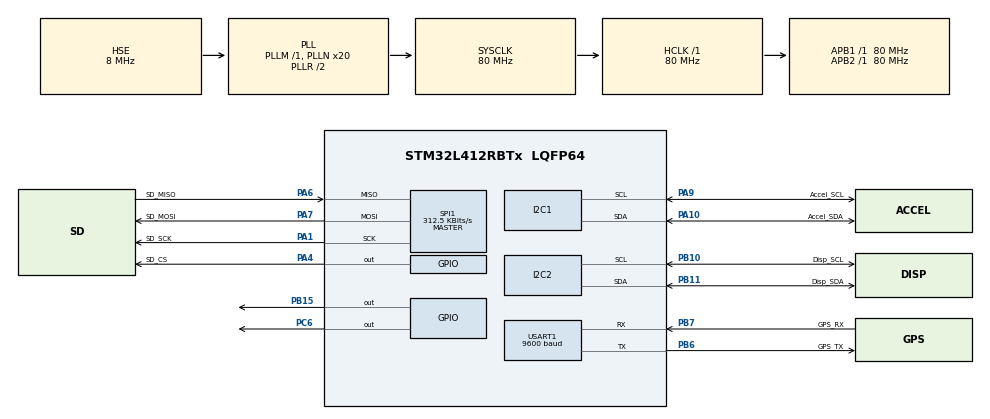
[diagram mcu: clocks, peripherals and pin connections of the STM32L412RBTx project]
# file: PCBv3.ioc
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I2C1.Timing=0x10909CEC
I2C2.Timing=0x10909CEC
Mcu.Family=STM32L4
Mcu.Name=STM32L412RBTx
Mcu.Package=LQFP64
NVIC.PriorityGroup=NVIC_PRIORITYGROUP_4
NVIC.USART1_IRQn=true\:0\:0\:false\:false\:true\:true\:true\:true
PA1.GPIO_Label=SD_SCK
PA1.Mode=Full_Duplex_Master
PA1.Signal=SPI1_SCK
PA10.GPIO_Label=Accel_SDA
PA10.Mode=I2C
PA10.Signal=I2C1_SDA
PA4.GPIO_Label=SD_CS
PA4.Signal=GPIO_Output
PA6.GPIO_Label=SD_MISO
PA6.Mode=Full_Duplex_Master
PA6.Signal=SPI1_MISO
PA7.GPIO_Label=SD_MOSI
PA7.Mode=Full_Duplex_Master
PA7.Signal=SPI1_MOSI
PA9.GPIO_Label=Accel_SCL
PA9.Mode=I2C
PA9.Signal=I2C1_SCL
PB10.GPIO_Label=Disp_SCL
PB10.Mode=I2C
PB10.Signal=I2C2_SCL
PB11.GPIO_Label=Disp_SDA
PB11.Mode=I2C
PB11.Signal=I2C2_SDA
PB15.Signal=GPIO_Output
PB6.GPIO_Label=GPS_TX
PB6.Mode=Asynchronous
PB6.Signal=USART1_TX
PB7.GPIO_Label=GPS_RX
PB7.Mode=Asynchronous
PB7.Signal=USART1_RX
PC6.Signal=GPIO_Output
PH0-OSC_IN\ (PH0).Mode=HSE-External-Oscillator
PH0-OSC_IN\ (PH0).Signal=RCC_OSC_IN
PH1-OSC_OUT\ (PH1).Mode=HSE-External-Oscillator
PH1-OSC_OUT\ (PH1).Signal=RCC_OSC_OUT
ProjectManager.HeapSize=0x2000
ProjectManager.StackSize=0x4000
ProjectManager.TargetToolchain=STM32CubeIDE
RCC.ADCFreq_Value=80000000
RCC.AHBFreq_Value=80000000
RCC.APB1Freq_Value=80000000
RCC.APB1TimFreq_Value=80000000
RCC.APB2Freq_Value=80000000
RCC.APB2TimFreq_Value=80000000
RCC.CortexFreq_Value=80000000
RCC.HCLKFreq_Value=80000000
RCC.HSE_VALUE=8000000
RCC.HSI48_VALUE=48000000
RCC.HSI_VALUE=16000000
RCC.LSE_VALUE=32768
RCC.MSI_VALUE=4000000
RCC.PLLN=20
RCC.PLLSourceVirtual=RCC_PLLSOURCE_HSE
RCC.SYSCLKFreq_VALUE=80000000
RCC.SYSCLKSource=RCC_SYSCLKSOURCE_PLLCLK
RCC.USBFreq_Value=4000000
RCC.VCOOutputFreq_Value=160000000
SPI1.BaudRatePrescaler=SPI_BAUDRATEPRESCALER_256
SPI1.CalculateBaudRate=312.5 KBits/s
SPI1.DataSize=SPI_DATASIZE_8BIT
SPI1.Direction=SPI_DIRECTION_2LINES
SPI1.Mode=SPI_MODE_MASTER
SPI1.VirtualType=VM_MASTER
USART1.BaudRate=9600
USART1.OverrunDisableParam=ADVFEATURE_OVERRUN_DISABLE
USART1.SwapParam=ADVFEATURE_SWAP_DISABLE
USART1.VirtualMode-Asynchronous=VM_ASYNC
VP_FATFS_VS_Generic.Mode=User_defined
board=custom

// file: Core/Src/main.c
/* USER CODE BEGIN Header */
/**
  ******************************************************************************
  * @file           : main.c
  * @brief          : Main program body
  ******************************************************************************
  * @attention
  *
  * Copyright (c) 2023 STMicroelectronics.
  * All rights reserved.
  *
  * This software is licensed under terms that can be found in the LICENSE file
  * in the root directory of this software component.
  * If no LICENSE file comes with this software, it is provided AS-IS.
  *
  ******************************************************************************
  */
/* USER CODE END Header */
#include "main.h"
#include "fatfs.h"

/* USER CODE BEGIN Includes */
#include <string.h>
#include <stdio.h>
#include <stdlib.h>
#include "stm32l4xx.h"
#include "GPS.h"
#include "I2C.h"
#include "ssd1306.h"
#include "lis3dh.h"
#include <stdarg.h>

/* USER CODE END Includes */

I2C_HandleTypeDef hi2c1;
I2C_HandleTypeDef hi2c2;
SPI_HandleTypeDef hspi1;
UART_HandleTypeDef huart1;

HAL_StatusTypeDef status;

void SystemClock_Config(void);
static void MX_GPIO_Init(void);
static void MX_I2C1_Init(void);
static void MX_I2C2_Init(void);
static void MX_SPI1_Init(void);
static void MX_USART1_UART_Init(void);

lis3dh_t lis3dh;

/* Longitude and Latitude variables used for reading and writing */
double cur_lat = 0;
double cur_lon = 0;
double pre_lat = 0;
double pre_lon = 0;

/* Time is 9 characters long, so 9 bytes */
char cur_time[9];
char pre_time[9];

/* Reads altitude variable, not currently used */
double alt = 0;

/* GPS buffers */
char nmea_buf[128]; //This is used for every NMEA sentence
char nmea_gga[128]; //This stores only GGA sentences
uint8_t nmea; //Holds integer character for every interrupt on UART1
uint8_t i = 0; //Index for NMEA sentences

/*
 * This is the callback function that gets called by the HAL
 * library when a UART receive operation is complete. Once interrupt
 * occurs, this function is called. It stores ASCII (integer representation)
 * into buffer. Once GGA sentence is found, latitude, longitude and time are
 * stored to global variables. Start another interrupt reception
 * once function is complete.
 */
void HAL_UART_RxCpltCallback(UART_HandleTypeDef *huart) {
    if (huart == &huart1) {

        nmea_buf[i++] = nmea; //store character

        //check if sentence is complete or if buffer overflow occurs
        if (nmea == '\n' || i >= sizeof(nmea_buf) - 1) {
        	if(nmea_buf[3]=='G' && nmea_buf[4]=='G' && nmea_buf[5] == 'A') //check for GGA sentence
        	{
        		memcpy(nmea_gga, nmea_buf, 128); //copy general buffer to GGA buffer
        		cur_lat = get_lat(nmea_gga);
        		cur_lon = get_lon(nmea_gga);
        		get_time(nmea_gga, pre_time);
        		alt = get_alt(nmea_gga);
        	}

            memset(nmea_buf, 0, sizeof(nmea_buf)); //clear general buffer
            i = 0; //reset index
        }

        // Start next UART character reception
        HAL_UART_Receive_IT(&huart1, &nmea, 1);
        if(status != HAL_OK)
		{
			HAL_GPIO_TogglePin(GPIOB, GPIO_PIN_13);
			while(1);
		}
    }
}

int main(void)
{
	/* Reset of all peripherals, Initializes the Flash interface and the Systick. */
	HAL_Init();

	/* Configure the system clock */
	SystemClock_Config();

	/* Initialize all configured peripherals */
	MX_GPIO_Init();
	MX_I2C1_Init();
	MX_I2C2_Init();
	MX_SPI1_Init();
	MX_USART1_UART_Init();
	MX_FATFS_Init();

	// Allocate a buffer for reading data from the sensor.
	// Two bytes required to read X accelerometer data.
	uint8_t x_accel_buf[2] = { 0 };
	signed int x_accel; //raw x acceleration

	/* Buffer to write variables to display */
	char display_buf[16];

	/* Variables for state machine */
	uint8_t state = BELOW; //arbitrary starting point
	uint16_t steps = 0; //total steps

	//some variables for FatFs
	FATFS FatFs; 	//Fatfs handle
	FIL fil; 		//File handle
	UINT bytesWrote;
	FRESULT fres;
	BYTE writedisplay_buf[35];
	char sd1[35]; //buffer for SD write, 35 characters always

	float total_distance = 0;
	float new_distance;
	float miles;

	HAL_Delay(1000); //Allow for microSD to settle (initialize everything)

	/* Create new file on MicroSD */
	fres = f_mount(&FatFs, "", 1); //1=mount now
	if(fres != FR_OK) {
		HAL_GPIO_TogglePin(GPIOC, GPIO_PIN_6);
		while(1);
	}
	fres = f_open(&fil, "crds.txt", FA_CREATE_ALWAYS | FA_OPEN_ALWAYS);
	if(fres != FR_OK) {
		HAL_GPIO_TogglePin(GPIOC, GPIO_PIN_6);
		while(1);
	}
	fres = f_close(&fil);
	if(fres != FR_OK) {
		HAL_GPIO_TogglePin(GPIOC, GPIO_PIN_6);
		while(1);
	}
	fres = f_mount(NULL, "", 0); //0=demount
	if(fres != FR_OK) {
		HAL_GPIO_TogglePin(GPIOC, GPIO_PIN_6);
		while(1);
	}

	/* Initialize accelerometer */
	status = lis3dh_init(&lis3dh, &hi2c1, x_accel_buf, 2);
	if (status != HAL_OK)
	{
		HAL_GPIO_TogglePin(GPIOB, GPIO_PIN_13);
		while(1);
	}

	/* Preliminary display of Steps and distance */
	ssd1306_Init();
	ssd1306_SetCursor(2,0);
	ssd1306_WriteString("Steps:", Font_11x18, White);
	ssd1306_SetCursor(2,20);
	ssd1306_WriteString("Distance:", Font_11x18, White);
	ssd1306_UpdateScreen();

	/* Start character interrupt interrupt */
	status = HAL_UART_Receive_IT(&huart1, &nmea, 1);
	if(status != HAL_OK)
	{
		HAL_GPIO_TogglePin(GPIOB, GPIO_PIN_13);
		while(1);
	}

	while (1)
	{
		/* Waits predetermined number of samples, then updates screen */
		for(int i = 0; i < NUM_SAMPLES; i++)
		{
			HAL_Delay(50); //20Hz sampling rate

			/* State machine  */
			if(lis3dh_xyz_available(&lis3dh)) {
				status = lis3dh_get_xyz(&lis3dh);
				if(status != HAL_OK)
				{
					HAL_GPIO_TogglePin(GPIOB, GPIO_PIN_13);
					while(1);
				}

				x_accel = lis3dh.x; //get x acceleration

				switch(state) {
					case TOP: //if in TOP state
						if(x_accel < THRESH_LOW) { //if acceleration drops below threshold
							steps += 1; //add one step
							state = BELOW; //change state
						}
						break;
					case BELOW: //if in BOTTOM state
						if(x_accel > THRESH_HIGH) { //if acceleration surpasses threshold
							state = TOP; //change states
						}
						break;
				}
			}
		}

		/* Write Steps to display */
		ssd1306_SetCursor(70,0);
		ssd1306_WriteString(itoa(steps,display_buf,10), Font_11x18, White);

		/* Chacks for GPS lock, lat and long will be zero in this case*/
		if((pre_lat == 0) || (pre_lon == 0) || (cur_lat == 0) || (cur_lon == 0)) {
		  ssd1306_SetCursor(2,50);
		  ssd1306_WriteString("Need GPS Lock", Font_7x10, White);
		  ssd1306_UpdateScreen();
		}
		else {
			sprintf(sd1,"%fN,%fW,%s",pre_lat,pre_lon,pre_time); //write lat,long,time to sd card buffer

			fres = f_mount(&FatFs, "", 1); //1=mount now
			if(fres != FR_OK) {
				HAL_GPIO_TogglePin(GPIOC, GPIO_PIN_6);
				while(1);
			}

			fres = f_open(&fil, "crds.txt", FA_WRITE | FA_OPEN_ALWAYS);
			if(fres == FR_OK) {
				f_lseek(&fil, f_size(&fil)); //seek through file to find next line
				strncpy((char*)writedisplay_buf, sd1, 35); //copy general string to required sd card buffer
				fres = f_write(&fil, writedisplay_buf, 35, &bytesWrote);
				if(fres != FR_OK) {
					HAL_GPIO_TogglePin(GPIOC, GPIO_PIN_6);
					while(1);
				}
			}
			else {
				HAL_GPIO_TogglePin(GPIOC, GPIO_PIN_6);
				while(1);
			}

			f_close(&fil); //close file

			f_mount(NULL, "", 0); //dismout file

			new_distance = calculateDistance(pre_lat, pre_lon, cur_lat, cur_lon);
			if(new_distance > MIN_GPS_DISTANCE){ //prevent GPS drift when still
			  total_distance += new_distance;
			}
			if(total_distance < 400) //display meters
			{
			  sprintf(display_buf,"%0.2f m     ",total_distance);
			}
			else{ //change from meters to miles
			  miles = total_distance / METERS_TO_MILES;
			  sprintf(display_buf,"%0.2f Mi     ",miles);
			}
			ssd1306_SetCursor(2,40);
			ssd1306_WriteString(display_buf, Font_11x18, White);
			ssd1306_UpdateScreen();

		}
			/* update present values to past */
			pre_lat = cur_lat;
			pre_lon = cur_lon;
			strcpy(pre_time, cur_time);
	}
}

void SystemClock_Config(void)
{
  RCC_OscInitTypeDef RCC_OscInitStruct = {0};
  RCC_ClkInitTypeDef RCC_ClkInitStruct = {0};

  /** Configure the main internal regulator output voltage
  */
  if (HAL_PWREx_ControlVoltageScaling(PWR_REGULATOR_VOLTAGE_SCALE1) != HAL_OK)
  {
    Error_Handler();
  }

  /** Initializes the RCC Oscillators according to the specified parameters
  * in the RCC_OscInitTypeDef structure.
  */
  RCC_OscInitStruct.OscillatorType = RCC_OSCILLATORTYPE_HSE;
  RCC_OscInitStruct.HSEState = RCC_HSE_ON;
  RCC_OscInitStruct.PLL.PLLState = RCC_PLL_ON;
  RCC_OscInitStruct.PLL.PLLSource = RCC_PLLSOURCE_HSE;
  RCC_OscInitStruct.PLL.PLLM = 1;
  RCC_OscInitStruct.PLL.PLLN = 20;
  RCC_OscInitStruct.PLL.PLLQ = RCC_PLLQ_DIV2;
  RCC_OscInitStruct.PLL.PLLR = RCC_PLLR_DIV2;
  if (HAL_RCC_OscConfig(&RCC_OscInitStruct) != HAL_OK)
  {
    Error_Handler();
  }

  /** Initializes the CPU, AHB and APB buses clocks
  */
  RCC_ClkInitStruct.ClockType = RCC_CLOCKTYPE_HCLK|RCC_CLOCKTYPE_SYSCLK
                              |RCC_CLOCKTYPE_PCLK1|RCC_CLOCKTYPE_PCLK2;
  RCC_ClkInitStruct.SYSCLKSource = RCC_SYSCLKSOURCE_PLLCLK;
  RCC_ClkInitStruct.AHBCLKDivider = RCC_SYSCLK_DIV1;
  RCC_ClkInitStruct.APB1CLKDivider = RCC_HCLK_DIV1;
  RCC_ClkInitStruct.APB2CLKDivider = RCC_HCLK_DIV1;

  if (HAL_RCC_ClockConfig(&RCC_ClkInitStruct, FLASH_LATENCY_4) != HAL_OK)
  {
    Error_Handler();
  }
}

static void MX_I2C1_Init(void)
{

  hi2c1.Instance = I2C1;
  hi2c1.Init.Timing = 0x10909CEC;
  hi2c1.Init.OwnAddress1 = 0;
  hi2c1.Init.AddressingMode = I2C_ADDRESSINGMODE_7BIT;
  hi2c1.Init.DualAddressMode = I2C_DUALADDRESS_DISABLE;
  hi2c1.Init.OwnAddress2 = 0;
  hi2c1.Init.OwnAddress2Masks = I2C_OA2_NOMASK;
  hi2c1.Init.GeneralCallMode = I2C_GENERALCALL_DISABLE;
  hi2c1.Init.NoStretchMode = I2C_NOSTRETCH_DISABLE;
  if (HAL_I2C_Init(&hi2c1) != HAL_OK)
  {
    Error_Handler();
  }

  /** Configure Analogue filter
  */
  if (HAL_I2CEx_ConfigAnalogFilter(&hi2c1, I2C_ANALOGFILTER_ENABLE) != HAL_OK)
  {
    Error_Handler();
  }

  /** Configure Digital filter
  */
  if (HAL_I2CEx_ConfigDigitalFilter(&hi2c1, 0) != HAL_OK)
  {
    Error_Handler();
  }

}

static void MX_I2C2_Init(void)
{

  hi2c2.Instance = I2C2;
  hi2c2.Init.Timing = 0x10909CEC;
  hi2c2.Init.OwnAddress1 = 0;
  hi2c2.Init.AddressingMode = I2C_ADDRESSINGMODE_7BIT;
  hi2c2.Init.DualAddressMode = I2C_DUALADDRESS_DISABLE;
  hi2c2.Init.OwnAddress2 = 0;
  hi2c2.Init.OwnAddress2Masks = I2C_OA2_NOMASK;
  hi2c2.Init.GeneralCallMode = I2C_GENERALCALL_DISABLE;
  hi2c2.Init.NoStretchMode = I2C_NOSTRETCH_DISABLE;
  if (HAL_I2C_Init(&hi2c2) != HAL_OK)
  {
    Error_Handler();
  }

  /** Configure Analogue filter
  */
  if (HAL_I2CEx_ConfigAnalogFilter(&hi2c2, I2C_ANALOGFILTER_ENABLE) != HAL_OK)
  {
    Error_Handler();
  }

  /** Configure Digital filter
  */
  if (HAL_I2CEx_ConfigDigitalFilter(&hi2c2, 0) != HAL_OK)
  {
    Error_Handler();
  }

}

static void MX_SPI1_Init(void)
{

  /* SPI1 parameter configuration*/
  hspi1.Instance = SPI1;
  hspi1.Init.Mode = SPI_MODE_MASTER;
  hspi1.Init.Direction = SPI_DIRECTION_2LINES;
  hspi1.Init.DataSize = SPI_DATASIZE_8BIT;
  hspi1.Init.CLKPolarity = SPI_POLARITY_LOW;
  hspi1.Init.CLKPhase = SPI_PHASE_1EDGE;
  hspi1.Init.NSS = SPI_NSS_SOFT;
  hspi1.Init.BaudRatePrescaler = SPI_BAUDRATEPRESCALER_256;
  hspi1.Init.FirstBit = SPI_FIRSTBIT_MSB;
  hspi1.Init.TIMode = SPI_TIMODE_DISABLE;
  hspi1.Init.CRCCalculation = SPI_CRCCALCULATION_DISABLE;
  hspi1.Init.CRCPolynomial = 7;
  hspi1.Init.CRCLength = SPI_CRC_LENGTH_DATASIZE;
  hspi1.Init.NSSPMode = SPI_NSS_PULSE_ENABLE;
  if (HAL_SPI_Init(&hspi1) != HAL_OK)
  {
    Error_Handler();
  }

}

static void MX_USART1_UART_Init(void)
{

  huart1.Instance = USART1;
  huart1.Init.BaudRate = 9600;
  huart1.Init.WordLength = UART_WORDLENGTH_8B;
  huart1.Init.StopBits = UART_STOPBITS_1;
  huart1.Init.Parity = UART_PARITY_NONE;
  huart1.Init.Mode = UART_MODE_TX_RX;
  huart1.Init.HwFlowCtl = UART_HWCONTROL_NONE;
  huart1.Init.OverSampling = UART_OVERSAMPLING_16;
  huart1.Init.OneBitSampling = UART_ONE_BIT_SAMPLE_DISABLE;
  huart1.AdvancedInit.AdvFeatureInit = UART_ADVFEATURE_RXOVERRUNDISABLE_INIT;
  huart1.AdvancedInit.OverrunDisable = UART_ADVFEATURE_OVERRUN_DISABLE;
  if (HAL_UART_Init(&huart1) != HAL_OK)
  {
    Error_Handler();
  }

}

static void MX_GPIO_Init(void)
{
  GPIO_InitTypeDef GPIO_InitStruct = {0};

  /* GPIO Ports Clock Enable */
  __HAL_RCC_GPIOH_CLK_ENABLE();
  __HAL_RCC_GPIOA_CLK_ENABLE();
  __HAL_RCC_GPIOB_CLK_ENABLE();
  __HAL_RCC_GPIOC_CLK_ENABLE();

  /*Configure GPIO pin Output Level */
  HAL_GPIO_WritePin(SD_CS_GPIO_Port, SD_CS_Pin, GPIO_PIN_RESET);

  /*Configure GPIO pin Output Level */
  HAL_GPIO_WritePin(GPIOB, GPIO_PIN_15, GPIO_PIN_RESET);

  /*Configure GPIO pin Output Level */
  HAL_GPIO_WritePin(GPIOC, GPIO_PIN_6, GPIO_PIN_RESET);

  /*Configure GPIO pin : SD_CS_Pin */
  GPIO_InitStruct.Pin = SD_CS_Pin;
  GPIO_InitStruct.Mode = GPIO_MODE_OUTPUT_PP;
  GPIO_InitStruct.Pull = GPIO_NOPULL;
  GPIO_InitStruct.Speed = GPIO_SPEED_FREQ_LOW;
  HAL_GPIO_Init(SD_CS_GPIO_Port, &GPIO_InitStruct);

  /*Configure GPIO pin : PB15 */
  GPIO_InitStruct.Pin = GPIO_PIN_15;
  GPIO_InitStruct.Mode = GPIO_MODE_OUTPUT_PP;
  GPIO_InitStruct.Pull = GPIO_NOPULL;
  GPIO_InitStruct.Speed = GPIO_SPEED_FREQ_LOW;
  HAL_GPIO_Init(GPIOB, &GPIO_InitStruct);

  /*Configure GPIO pin : PC6 */
  GPIO_InitStruct.Pin = GPIO_PIN_6;
  GPIO_InitStruct.Mode = GPIO_MODE_OUTPUT_PP;
  GPIO_InitStruct.Pull = GPIO_NOPULL;
  GPIO_InitStruct.Speed = GPIO_SPEED_FREQ_LOW;
  HAL_GPIO_Init(GPIOC, &GPIO_InitStruct);

}

void Error_Handler(void)
{
  __disable_irq();
  while (1)
  {
  }
}
